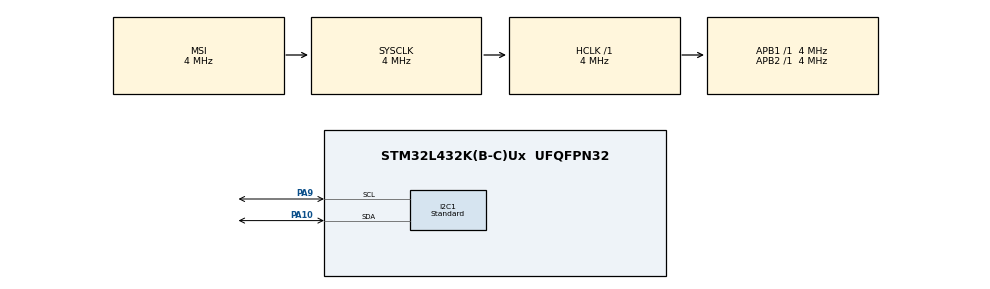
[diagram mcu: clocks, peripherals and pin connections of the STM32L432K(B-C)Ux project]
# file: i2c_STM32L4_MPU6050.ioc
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I2C1.I2C_Speed_Mode=I2C_Standard
I2C1.Timing=0x00000E14
Mcu.Family=STM32L4
Mcu.Name=STM32L432K(B-C)Ux
Mcu.Package=UFQFPN32
NVIC.PriorityGroup=NVIC_PRIORITYGROUP_4
PA0.Mode=HSE-External-Clock-Source-for-LittleOrca
PA0.Signal=RCC_CK_IN
PA10.Mode=I2C
PA10.Signal=I2C1_SDA
PA9.Mode=I2C
PA9.Signal=I2C1_SCL
ProjectManager.HeapSize=0x200
ProjectManager.StackSize=0x400
ProjectManager.TargetToolchain=STM32CubeIDE
RCC.ADCFreq_Value=16000000
RCC.AHBFreq_Value=4000000
RCC.APB1Freq_Value=4000000
RCC.APB1TimFreq_Value=4000000
RCC.APB2Freq_Value=4000000
RCC.APB2TimFreq_Value=4000000
RCC.CortexFreq_Value=4000000
RCC.HCLKFreq_Value=4000000
RCC.HSI48_VALUE=48000000
RCC.HSI_VALUE=16000000
RCC.MSI_VALUE=4000000
RCC.PLLN=16
RCC.SYSCLKFreq_VALUE=4000000
RCC.USBFreq_Value=16000000
RCC.VCOOutputFreq_Value=64000000
board=custom

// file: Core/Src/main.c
/* USER CODE BEGIN Header */
/**
  ******************************************************************************
  * @file           : main.c
  * @brief          : Main program body
  ******************************************************************************
  * @attention
  *
  * Copyright (c) 2024 STMicroelectronics.
  * All rights reserved.
  *
  * This software is licensed under terms that can be found in the LICENSE file
  * in the root directory of this software component.
  * If no LICENSE file comes with this software, it is provided AS-IS.
  *
  ******************************************************************************
  */
/* USER CODE END Header */
#include "main.h"

/* USER CODE BEGIN PD */
#define MPU6050_address (0x68<<1)+0 //device address with AD0 to GND
#define who_am_i_reg_add 0x75//register address
/* USER CODE END PD */

I2C_HandleTypeDef hi2c1;

void SystemClock_Config(void);
static void MX_GPIO_Init(void);
static void MX_I2C1_Init(void);

int main(void)
{
  /* USER CODE BEGIN 1 */
	HAL_StatusTypeDef ret; //to store the return of the function
	 uint8_t rData; // data buffer to store the data read
  /* USER CODE END 1 */

  /* MCU Configuration--------------------------------------------------------*/

  /* Reset of all peripherals, Initializes the Flash interface and the Systick. */
  HAL_Init();

  /* Configure the system clock */
  SystemClock_Config();

  /* Initialize all configured peripherals */
  MX_GPIO_Init();
  MX_I2C1_Init();
  /* USER CODE BEGIN 2 */

  	ret=HAL_I2C_Mem_Read(&hi2c1,MPU6050_address,who_am_i_reg_add, 1,&rData, 1, 1000);
  /* USER CODE END 2 */

  /* Infinite loop */
  while (1)
  {

  }
}

void SystemClock_Config(void)
{
  RCC_OscInitTypeDef RCC_OscInitStruct = {0};
  RCC_ClkInitTypeDef RCC_ClkInitStruct = {0};

  /** Configure the main internal regulator output voltage
  */
  if (HAL_PWREx_ControlVoltageScaling(PWR_REGULATOR_VOLTAGE_SCALE1) != HAL_OK)
  {
    Error_Handler();
  }

  /** Initializes the RCC Oscillators according to the specified parameters
  * in the RCC_OscInitTypeDef structure.
  */
  RCC_OscInitStruct.OscillatorType = RCC_OSCILLATORTYPE_MSI;
  RCC_OscInitStruct.MSIState = RCC_MSI_ON;
  RCC_OscInitStruct.MSICalibrationValue = 0;
  RCC_OscInitStruct.MSIClockRange = RCC_MSIRANGE_6;
  RCC_OscInitStruct.PLL.PLLState = RCC_PLL_NONE;
  if (HAL_RCC_OscConfig(&RCC_OscInitStruct) != HAL_OK)
  {
    Error_Handler();
  }

  /** Initializes the CPU, AHB and APB buses clocks
  */
  RCC_ClkInitStruct.ClockType = RCC_CLOCKTYPE_HCLK|RCC_CLOCKTYPE_SYSCLK
                              |RCC_CLOCKTYPE_PCLK1|RCC_CLOCKTYPE_PCLK2;
  RCC_ClkInitStruct.SYSCLKSource = RCC_SYSCLKSOURCE_MSI;
  RCC_ClkInitStruct.AHBCLKDivider = RCC_SYSCLK_DIV1;
  RCC_ClkInitStruct.APB1CLKDivider = RCC_HCLK_DIV1;
  RCC_ClkInitStruct.APB2CLKDivider = RCC_HCLK_DIV1;

  if (HAL_RCC_ClockConfig(&RCC_ClkInitStruct, FLASH_LATENCY_0) != HAL_OK)
  {
    Error_Handler();
  }
}

static void MX_I2C1_Init(void)
{

  hi2c1.Instance = I2C1;
  hi2c1.Init.Timing = 0x00000E14;
  hi2c1.Init.OwnAddress1 = 0;
  hi2c1.Init.AddressingMode = I2C_ADDRESSINGMODE_7BIT;
  hi2c1.Init.DualAddressMode = I2C_DUALADDRESS_DISABLE;
  hi2c1.Init.OwnAddress2 = 0;
  hi2c1.Init.OwnAddress2Masks = I2C_OA2_NOMASK;
  hi2c1.Init.GeneralCallMode = I2C_GENERALCALL_DISABLE;
  hi2c1.Init.NoStretchMode = I2C_NOSTRETCH_DISABLE;
  if (HAL_I2C_Init(&hi2c1) != HAL_OK)
  {
    Error_Handler();
  }

  /** Configure Analogue filter
  */
  if (HAL_I2CEx_ConfigAnalogFilter(&hi2c1, I2C_ANALOGFILTER_ENABLE) != HAL_OK)
  {
    Error_Handler();
  }

  /** Configure Digital filter
  */
  if (HAL_I2CEx_ConfigDigitalFilter(&hi2c1, 0) != HAL_OK)
  {
    Error_Handler();
  }

}

static void MX_GPIO_Init(void)
{

  /* GPIO Ports Clock Enable */
  __HAL_RCC_GPIOA_CLK_ENABLE();

}

void Error_Handler(void)
{
  __disable_irq();
  while (1)
  {
  }
}
